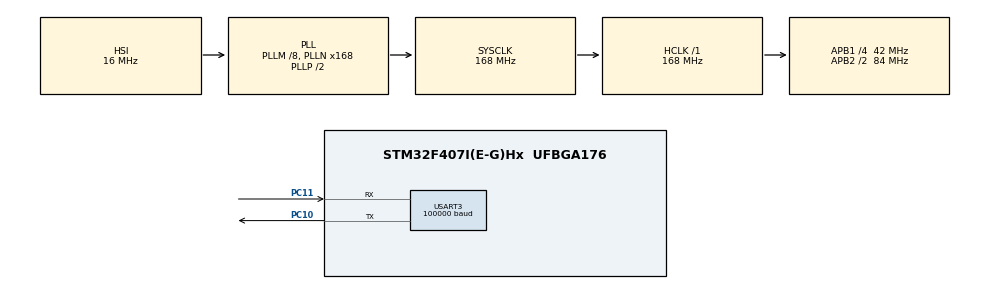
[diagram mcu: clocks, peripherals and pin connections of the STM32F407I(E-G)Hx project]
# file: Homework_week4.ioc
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Dma.Request0=USART3_RX
Dma.USART3_RX.0.Direction=DMA_PERIPH_TO_MEMORY
Dma.USART3_RX.0.FIFOMode=DMA_FIFOMODE_DISABLE
Dma.USART3_RX.0.Instance=DMA1_Stream1
Dma.USART3_RX.0.MemDataAlignment=DMA_MDATAALIGN_BYTE
Dma.USART3_RX.0.MemInc=DMA_MINC_ENABLE
Dma.USART3_RX.0.Mode=DMA_NORMAL
Dma.USART3_RX.0.PeriphDataAlignment=DMA_PDATAALIGN_BYTE
Dma.USART3_RX.0.PeriphInc=DMA_PINC_DISABLE
Dma.USART3_RX.0.Priority=DMA_PRIORITY_LOW
Mcu.Family=STM32F4
Mcu.Name=STM32F407I(E-G)Hx
Mcu.Package=UFBGA176
NVIC.DMA1_Stream1_IRQn=true\:0\:0\:false\:false\:true\:false\:true\:true
NVIC.PriorityGroup=NVIC_PRIORITYGROUP_4
NVIC.USART3_IRQn=true\:0\:0\:false\:false\:true\:true\:true\:true
PA13.Mode=Serial_Wire
PA13.Signal=SYS_JTMS-SWDIO
PA14.Mode=Serial_Wire
PA14.Signal=SYS_JTCK-SWCLK
PC10.Mode=Asynchronous
PC10.Signal=USART3_TX
PC11.Mode=Asynchronous
PC11.Signal=USART3_RX
PH0-OSC_IN.Mode=HSE-External-Oscillator
PH0-OSC_IN.Signal=RCC_OSC_IN
PH1-OSC_OUT.Mode=HSE-External-Oscillator
PH1-OSC_OUT.Signal=RCC_OSC_OUT
ProjectManager.HeapSize=0x200
ProjectManager.StackSize=0x400
ProjectManager.TargetToolchain=Makefile
RCC.48MHZClocksFreq_Value=84000000
RCC.AHBFreq_Value=168000000
RCC.APB1CLKDivider=RCC_HCLK_DIV4
RCC.APB1Freq_Value=42000000
RCC.APB1TimFreq_Value=84000000
RCC.APB2CLKDivider=RCC_HCLK_DIV2
RCC.APB2Freq_Value=84000000
RCC.APB2TimFreq_Value=168000000
RCC.CortexFreq_Value=168000000
RCC.HCLKFreq_Value=168000000
RCC.HSE_VALUE=12000000
RCC.HSI_VALUE=16000000
RCC.LSE_VALUE=32768
RCC.PLLM=8
RCC.PLLN=168
RCC.SYSCLKFreq_VALUE=168000000
RCC.SYSCLKSource=RCC_SYSCLKSOURCE_PLLCLK
RCC.VCOOutputFreq_Value=336000000
USART3.BaudRate=100000
USART3.Parity=PARITY_EVEN
USART3.StopBits=STOPBITS_2
USART3.VirtualMode=VM_ASYNC
USART3.WordLength=WORDLENGTH_9B
board=custom

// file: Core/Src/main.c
/* USER CODE BEGIN Header */
/**
  ******************************************************************************
  * @file           : main.c
  * @brief          : Main program body
  ******************************************************************************
  * @attention
  *
  * Copyright (c) 2026 STMicroelectronics.
  * All rights reserved.
  *
  * This software is licensed under terms that can be found in the LICENSE file
  * in the root directory of this software component.
  * If no LICENSE file comes with this software, it is provided AS-IS.
  *
  ******************************************************************************
  */
/* USER CODE END Header */
#include "main.h"
#include "dma.h"
#include "usart.h"
#include "gpio.h"

void SystemClock_Config(void);

/* USER CODE BEGIN 0 */
typedef struct{
uint8_t start_byte;
uint8_t flag_byte;
uint8_t stop_byte;

int16_t rocker_r_;
int16_t rocker_r1;
int16_t rocker_l_;
int16_t rocker_l1;
int16_t rocker_SWA;
int16_t rocker_SWB;
int16_t rocker_SWC;
int16_t rocker_SWD;
int16_t rocker_VRA;
int16_t rocker_VRB;

uint16_t error_protect;
uint16_t byte_lose;

}rc_;
rc_ rc_data;
uint8_t buf[255] = {0};
uint16_t CH[64];

uint8_t test = 0;

/* USER CODE END 0 */

int main(void)
{

  /* MCU Configuration--------------------------------------------------------*/

  /* Reset of all peripherals, Initializes the Flash interface and the Systick. */
  HAL_Init();

  /* Configure the system clock */
  SystemClock_Config();

  /* Initialize all configured peripherals */
  MX_GPIO_Init();
  MX_DMA_Init();
  MX_USART3_UART_Init();
  /* USER CODE BEGIN 2 */

  HAL_UARTEx_ReceiveToIdle_DMA(&huart3,buf,25);
  __HAL_DMA_DISABLE_IT(huart3.hdmarx,DMA_IT_HT);

  /* USER CODE END 2 */

  /* Infinite loop */
  while(1)
  {

    /* USER CODE BEGIN 3 */
    test ++;
  }
  /* USER CODE END 3 */
}

void SystemClock_Config(void)
{
  RCC_OscInitTypeDef RCC_OscInitStruct = {0};
  RCC_ClkInitTypeDef RCC_ClkInitStruct = {0};

  /** Configure the main internal regulator output voltage
  */
  __HAL_RCC_PWR_CLK_ENABLE();
  __HAL_PWR_VOLTAGESCALING_CONFIG(PWR_REGULATOR_VOLTAGE_SCALE1);

  /** Initializes the RCC Oscillators according to the specified parameters
  * in the RCC_OscInitTypeDef structure.
  */
  RCC_OscInitStruct.OscillatorType = RCC_OSCILLATORTYPE_HSI;
  RCC_OscInitStruct.HSIState = RCC_HSI_ON;
  RCC_OscInitStruct.HSICalibrationValue = RCC_HSICALIBRATION_DEFAULT;
  RCC_OscInitStruct.PLL.PLLState = RCC_PLL_ON;
  RCC_OscInitStruct.PLL.PLLSource = RCC_PLLSOURCE_HSI;
  RCC_OscInitStruct.PLL.PLLM = 8;
  RCC_OscInitStruct.PLL.PLLN = 168;
  RCC_OscInitStruct.PLL.PLLP = RCC_PLLP_DIV2;
  RCC_OscInitStruct.PLL.PLLQ = 4;
  if (HAL_RCC_OscConfig(&RCC_OscInitStruct) != HAL_OK)
  {
    Error_Handler();
  }

  /** Initializes the CPU, AHB and APB buses clocks
  */
  RCC_ClkInitStruct.ClockType = RCC_CLOCKTYPE_HCLK|RCC_CLOCKTYPE_SYSCLK
                              |RCC_CLOCKTYPE_PCLK1|RCC_CLOCKTYPE_PCLK2;
  RCC_ClkInitStruct.SYSCLKSource = RCC_SYSCLKSOURCE_PLLCLK;
  RCC_ClkInitStruct.AHBCLKDivider = RCC_SYSCLK_DIV1;
  RCC_ClkInitStruct.APB1CLKDivider = RCC_HCLK_DIV4;
  RCC_ClkInitStruct.APB2CLKDivider = RCC_HCLK_DIV2;

  if (HAL_RCC_ClockConfig(&RCC_ClkInitStruct, FLASH_LATENCY_5) != HAL_OK)
  {
    Error_Handler();
  }
}

/* USER CODE BEGIN 4 */
void HAL_UARTEx_RxEventCallback(UART_HandleTypeDef *huart, uint16_t Size)
{
  if(huart == &huart3)
  {
    if(buf[0] == 0x0F)//检验帧头
    {
      rc_data.start_byte = buf[0];

      rc_data.error_protect = (rc_data.flag_byte >> 3) & 0X01;
      rc_data.byte_lose = (rc_data.flag_byte >> 2) & 0X01;
      //获得丢帧保护位和传输错误位

      if(rc_data.error_protect | rc_data.byte_lose == 1)//位运算判断是否至少一位=1
      {
        return;//信号有问题时退出函数
      }

      uint8_t numPtr = 1;//当前解析到buf的哪一位
      uint8_t Ptr = 0;
      uint16_t temp = 0;

      for(int i = 0,p = 0;i < 10;i ++)
      {
        CH[i] = 0;
        for(int j = 0;j < 11;j ++,p ++)
        {

          if(p > 7)//p溢出时
          {
            p = 0;
            numPtr ++;
          }
          //取位->按照j填充到目标里->最后消掉11前的位数
          //处理一个全1的掩码
          temp = -1;
          //把第j位改成需要的内容  p代表当前在buf[numPtr]的从低到高第p位
          temp &= (1 & (buf[numPtr] >> p)) << j;
          CH[i] |= temp;

        }
        //处理后取后11位
        CH[i] &= 0x07FF;
      }

      //CH[0] = ((int16_t)buf[1] >> 0 | (int16_t)buf[2] << 8) & 0x07ff - 1024 + 784;

      rc_data.rocker_r_ = CH[0] - 1024;
      rc_data.rocker_r1 = CH[1] - 1024;
      rc_data.rocker_l_ = CH[2] - 1024;
      rc_data.rocker_l1 = CH[3] - 1024;
      rc_data.rocker_SWA = CH[4] - 1024;
      rc_data.rocker_SWB = CH[5] - 1024;
      rc_data.rocker_SWC = CH[6] - 1024;
      rc_data.rocker_SWD = CH[7] - 1024;
      rc_data.rocker_VRA = CH[8] - 1024;
      rc_data.rocker_VRB = CH[9] - 1024;

      rc_data.flag_byte = buf[23];

        HAL_UARTEx_ReceiveToIdle_DMA(&huart3,buf,25);
      __HAL_DMA_DISABLE_IT(huart3.hdmarx,DMA_IT_HT);
    }
  }
}

void HAL_UART_ErrorCallback(UART_HandleTypeDef *huart)
{
  if(huart == &huart3)
  {
    HAL_UARTEx_ReceiveToIdle_DMA(&huart3,buf,25);
  __HAL_DMA_DISABLE_IT(huart3.hdmarx,DMA_IT_HT);
  }
}
/* USER CODE END 4 */

void Error_Handler(void)
{
  __disable_irq();
  while (1)
  {
  }
}
